# netx90_app register map
File version: 1.0
CPU: CM4 r0p1, little endian, MPU, FPU, 4 interrupt priority bits, 78 interrupts
Registers are 32-bit, read-write, reset 0x0 unless marked. A register's access mark holds for its fields unless they carry their own. Offsets are from the block's base; [hi:lo] are bit positions; {n}, {i} and the like mark numbered series.

## biss0_app
Base 0xFF802100
Same registers: biss1_app 0xFF802200
{0x0+8i} biss_scdata{i}_0 (i=0..6) — Sensor and Actuator Data
  [31:0] SCDATA{i}_0 — Slave{i} (SCD)single cycle data[31:0]
{0x4+8i} biss_scdata{i}_1 (i=0..7) — Sensor and Actuator Data
  [31:0] SCDATA{i}_1 — Slave{i} (SCD)single cycle data[63:32]
0x38 biss_scdata7_0 — Sensor and Actuator Data
  [31:0] SCDATA7_0 — Slave0 (SCD)single cycle data[31:0]
0x80 biss_rdata0 — Register Data
  [31:0] RDATA0 — - Using register access in control communication RDATA0: register data DWord0 - Using command/instructions in control communication IDS: ID-Select, command/instruction addressing combinable
{0x80+4i} biss_rdata{i} (i=1..15) — Register Data
  [31:0] RDATA{i} — register data DWord{i}
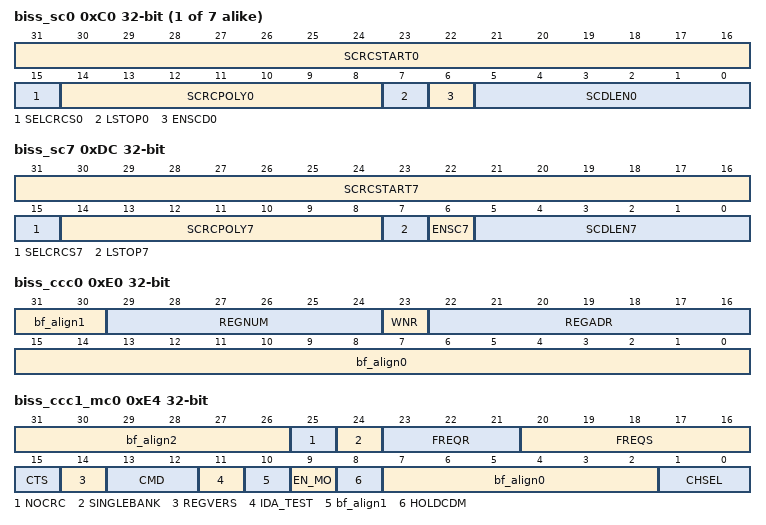
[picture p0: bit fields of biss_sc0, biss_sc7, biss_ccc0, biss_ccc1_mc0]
{0xC0+4i} biss_sc{i} (i=0..6) — Slave Configuration
  [31:16] SCRCSTART{i} — Start value for polynomial SCD CRC calculation
  [15] SELCRCS{i} — Selection between polynomial or length for SCD CRC polynomial 0: CRC bit length in SCRCLENx (see SCRCPOLYx) apply dedicated CRC polynomials 1: CRC polynomial(7:1) in SCRCPOLYx. SELCRCSx = 1 not applicable with CRC polynomial SCRCPOLYx(7:0) = 0x00
  [14:8] SCRCPOLY{i} — - SELCRCx == 0 ( SCRCLENx: polynomial selection by length for SCD CRC check) 0: CRC for single cycle data not present, CRC verification deactivated. SELCRCSx = 0b0 3: CRC polynomial = 0x0b 4: CRC polynomial = 0x13 5: CRC polynomial = 0x25 6: CRC polynomial = 0x43 7: CRC polynomial = 0x89 8: CRC polynomial = 0x12f 16: CRC polynomial = 0x190d9 ..: other CRC length are not permitted with SELCRCSx = 0 - SELCRCx == 1 (SCRCPOLYx: polynomial for SCD CRC check) 0x00 : CRC polynomial 0x00 not applicable with SELCRCSx = 1 0x01.. 0x7f: CRC polynomial for single cycle data = SCRCPOLYx(7:1) + 0x01
  [7] LSTOP{i} — - BISS mode(LSTOPx = Actuator stop bit control) 0: no leading STOP bit on single cycle actuator data 1: leading STOP bit on single cycle actuator data - SSI mode(GRAYSx = Enable SCD gray to binary conversion) 0: SSI single cycle data binary coded 1: SSI single cycle data gray coded
  [6] ENSCD{i} — Enable single cycle data 0: single cycle data not available 1: single cycle data available
  [5:0] SCDLEN{i} — Single cycle data length 0 : single cycle data length = 1 1 : single cycle data length = 2 ... single cycle data length = SCDLENx + 1 62: single cycle data length = 63 63: single cycle data length = 64
0xDC biss_sc7 — Slave Configuration
  [31:16] SCRCSTART7 — Start value for polynomial SCD CRC calculation
  [15] SELCRCS7 — Selection between polynomial or length for SCD CRC polynomial 0: CRC bit length in SCRCLENx (see SCRCPOLYx) apply dedicated CRC polynomials 1: CRC polynomial(7:1) in SCRCPOLYx. SELCRCSx = 1 not applicable with CRC polynomial SCRCPOLYx(7:0) = 0x00
  [14:8] SCRCPOLY7 — - SELCRCx == 0 (SCRCLENx: polynomial selection by length for SCD CRC check) 0: CRC for single cycle data not present, CRC verification deactivated. SELCRCSx = 0b0 3: CRC polynomial = 0x0b 4: CRC polynomial = 0x13 5: CRC polynomial = 0x25 6: CRC polynomial = 0x43 7: CRC polynomial = 0x89 8: CRC polynomial = 0x12f 16: CRC polynomial = 0x190d9 ..: other CRC length are not permitted with SELCRCSx = 0 - SELCRCx == 1 (SCRCPOLYx: polynomial for SCD CRC check) 0x00 : CRC polynomial 0x00 not applicable with SELCRCSx = 1 0x01.. 0x7f: CRC polynomial for single cycle data = SCRCPOLYx(7:1) + 0x01
  [7] LSTOP7 — - BISS mode(LSTOPx = Actuator stop bit control) 0: no leading STOP bit on single cycle actuator data 1: leading STOP bit on single cycle actuator data - SSI mode(GRAYSx = Enable SCD gray to binary conversion) 0: SSI single cycle data binary coded 1: SSI single cycle data gray coded
  [6] ENSC7 — Enable single cycle data 0: single cycle data not available 1: single cycle data available
  [5:0] SCDLEN7 — Single cycle data length 0 : single cycle data length = 1 1 : single cycle data length = 2 ... single cycle data length = SCDLENx + 1 62: single cycle data length = 63 63: single cycle data length = 64
0xE0 biss_ccc0 (reset mask 0x3FFF0000) — Register Communication Configuration
  [31:30] bf_align1 — bitField alignment value for aeabi compatibility
  [29:24] REGNUM — Register data count 0x00 : register count = 1 0x01 ..0x3f: register count = REGNUM(5:0)+1
  [23] WNR — Register access read/write selector 0: read register data 1: write register data
  [22:16] REGADR — Register access start address 0x00 .. 0x7f
  [15:0] bf_align0 — bitField alignment value for aeabi compatibility
0xE4 biss_ccc1_mc0 (reset mask 0x3FFFB03) — Register Communication Configuration / Master Configuration
  [31:26] bf_align2 — bitField alignment value for aeabi compatibility
  [25] NOCRC — CRC for SCD not to be stored in RAM 0: CRC of SCD is stored RAM (only applicable with active CRC verification and CRC polynome > 0) 1: CRC of SCD not to be stored in RAM
  [24] SINGLEBANK — Use of only one RAM bank for SCD 0: two RAM banks are used for SCD 1: one RAM bank is used for SCD
  [23:21] FREQR — Frequency division register communication BiSS B 0 .. 7: freqSens/(2*(FREQ(7:5)+1)) 0: FreqSens/2 1: FreqSens/4 2: FreqSens/8 3: FreqSens/16 4: FreqSens/32 5: FreqSens/64 6: FreqSens/128 7: FreqSens/256
  [20:16] FREQS — Frequency division 0x00: fCLK/2 0x01: fCLK/4 0x02: fCLK/6 0x03: fCLK/8 ... 0x09: fCLK/20 ... 0x0d: fCLK/28 0x0e: fCLK/30 0x0f: fCLK/32 0x10: not permitted 0x11: fCLK/40 0x12: fCLK/60 0x13: fCLK/80 ... 0x1d: fCLK/280 0x1e: fCLK/300 0x1f: fCLK/320
  [15] CTS — Register transmission or instruction selector 0: command/instruction communication 1: register communication
  [14] REGVERS — BiSS model A/B or C selector - Using register access in control communication 0: register communication BiSS A/B 1: register communication BiSS C - Using command/instructions in control communication 0: not applicable with command/instruction communication 1: command communication BiSS C
  [13:12] CMD — - Using register access in control communication SLAVEID[2:1]: slave selector bit2_1 - Using command/instructions in control communication Command of access slave # default 0x00 0x00 .. 0x03: command/instruction 0b00 .. 0b11
  [11] IDA_TEST — - Using register access in control communication SLAVEID[0]: slave selector bit0 - Using command/instructions in control communication IDA_TEST: command/instruction execution control 0: the slaves feedback (IDA) is tested before execution (EX bit after IDA) 1: immediate execution
  [10] bf_align1 — bitField alignment value for aeabi compatibility
  [9] EN_MO — Enable output at MOx for actuator data or delayed start bit 0: MO forced to low 1: Parameterized processing time by master on MO signal active (length: MO_BUSY)
  [8] HOLDCDM — Hold CDM(control data master) 0: clock line high at end of cycle 1: clock line constant with CDM bit until start of next cycle
  [7:2] bf_align0 — bitField alignment value for aeabi compatibility
  [1:0] CHSEL — Channel selector 0: channel 1 used for control communication, channel 2 not used 1: channel 1 used for control communication, channel 2 not used 2: channel 2 used for control communication, channel 1 not used. Note: Channel 2 is not available with IC-MB4 TSSOP24 3: channel 1,2 used for control communication. Note: Channel 2 is not available with IC-MB4 TSSOP24
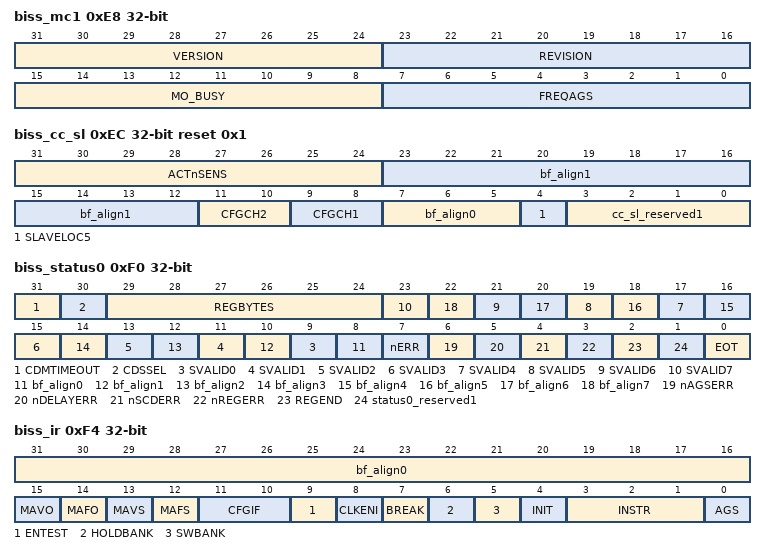
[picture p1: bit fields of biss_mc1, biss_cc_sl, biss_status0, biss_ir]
0xE8 biss_mc1 — Master Configuration
  [31:24] VERSION — Device identifier 0x83: iC-MB3 0x84: iC-MB4 .. 0xff
  [23:16] REVISION — Revision 0x10: Z(first revision) 0x11: Z1 0x12: Y .. 0xff
  [15:8] MO_BUSY — Delay of start bit at output MOx 0x00 .. 0xff: count of MA clocks as the parameterized processing time by master on MO signal Premise: EN_MO = 1
  [7:0] FREQAGS — AutoGetSens Frequency division 0x00.. 0x7b: fCLK/(20*(FREQAGS(6:0)+1)) 0x7c : AGSMIN( the master automatically restarts the next cycle after the prior was finished. AGSMIN is the fastest SCD rate with complete SCD cycles. ) 0x7d.. 0x7f: AGSINFINITE( the master does not automatically restart the next cycle after the prior one was finished. AGSINFINITE requires a trigger event to start the next SCD cycle. ) 0x80.. 0xff: fCLK/(625*(FREQAGS(6:0)+1))
0xEC biss_cc_sl reset 0x1 (reset mask 0xFF000F1F) — Channel Configuration
  [31:24] ACTnSENS — Sensor or actuator data selector 0x00: all slaves are sensors 0x01: slave 0 is actuator 0x02: slave 1 is actuator 0x04: slave 2 is actuator 0x08: slave 3 is actuator 0x10: slave 4 is actuator 0x20: slave 5 is actuator 0x40: slave 6 is actuator 0x80: slave 7 is actuator 0xff: all slaves are actuators
  [23:12] bf_align1 — bitField alignment value for aeabi compatibility
  [11:10] CFGCH2 — Channel 2 configuration 0x00: BiSS B 0x01: BiSS C 0x02: SSI 0x03: channel is not used
  [9:8] CFGCH1 — Channel 1 configuration 0x00: BiSS B 0x01: BiSS C 0x02: SSI 0x03: channel is not used
  [7:5] bf_align0 — bitField alignment value for aeabi compatibility
  [4] SLAVELOC5 — Slave location 0: slaves 4-7 are connected to channel 1 1: slaves 4-7 are connected to channel 2(only available with iC-MB4 QFN28)
  [3:0] cc_sl_reserved1 — no field descpription
0xF0 biss_status0 ro (reset mask 0xFFAAAAFF) — Status Information
  [31] CDMTIMEOUT — CDM(Control Data Master) timeout reached 0: CDMTIMEOUT not reached 1: CDMTIMEOUT reached
  [30] CDSSEL — CDS(Control Data Slave) bit from the selected channel
  [29:24] REGBYTES — Number of valid register data transmission in case of error 0x00 : after transfer: no register communication error 0x01 . 0x3f: after transfer: number of successfully transferred registers before register communication error
  [2n+9] SVALID{n} (n=0..7) — SCDATA{n} validity indication 0: SCD invalid 1: SCD valid The SVALIDx bit indicates the validity of each slaves SCD CRC verification. A prior set SVALIDx bit can be reset by writing 0 into the register.
  [2n+8] bf_align{n} (n=0..7) — bitField alignment value for aeabi compatibility
  [7] nERR — Transmission error (error at NER pin) 0: error 1: no error It is possible to connect other components to pin NER which can also generate an error message; this can then be read out via this bit.
  [6] nAGSERR — AGS error 0: AGS(Automatic Get Sensor data) watchdog error 1: no AGS watchdog error An AGS watchdog error is set during the automatic transmission of sensor data if no new cycle could be initiated; bit AGS in the command register is reset and the automatic request of sensor data aborted.
  [5] nDELAYERR — Missing start bit during register communication 0: delay error 1: no delay error
  [4] nSCDERR — Error in single cycle data transmission 0: error in last single cycle data transmission 1: no error in last single cycle data transmission
  [3] nREGERR — Error in register data transmission 0: error in last register data transmission 1: no error in last register data transmission
  [2] REGEND — Register data transmission completed 0: no valid register data available 1: register data transmission completed
  [1] status0_reserved1 — reserved value
  [0] EOT — Data transmission completed 0: data transmission active 1: data transmission finished
0xF4 biss_ir (reset mask 0xFFFF) — Instruction Register
  [31:16] bf_align0 — bitField alignment value for aeabi compatibility
  [15] MAVO — Not selected MA line control level 0: low definition of unselected(CHSEL) MA clock lines 1: high definition of unselected(CHSEL) MA clock lines
  [14] MAFO — Not selected MA line control selection 0: controlling unselected(CHSEL) MA clock line: using MA signal 1: controlling unselected(CHSEL) MA clock line: using MAVS level
  [13] MAVS — Selected MA line control level 0: low definition of selected(CHSEL) MA clock lines 1: high definition of selected(CHSEL) MA clock lines
  [12] MAFS — Selected MA line control selection 0: controlling selected/CHSEL) MA clock line: using MA signal 1: controlling selected(CHSEL) MA clock line: using MAVS level
  [11:10] CFGIF — Configure physical interface 0x00: TTL 0x01: CMOS 0x02: RS422 0x03: LVDS
  [9] ENTEST — Enable test interface 0: device in normal operation mode 1: device in test mode
  [8] CLKENI — Enable internal clock 0: the master clock is generated by an external clock oscillator 1: the master clock is generated by the basic clock of the internal 20MHz oscillator
  [7] BREAK — Data transmission interrupt 0: no change 1: abort data transmission nSCDERR, nREGERR, nDELAYERR, nAGSERR = 1, REGEND = 0 All current actions can be aborted using the BREAK command so that a defined state can be resumed if one of the sensors proves faulty, for example. BREAK= 1 aborts the active data transmission and all status information will be reset.
  [6] HOLDBANK — RAM bank control 0: no bank switching lock permitted 1: bank switching lock permitted During the readout of more than one sensor data register by the controller it is possible that the RAM banks in the master could be swapped over once a sensor data transmission is completed. So that the controller only reads related values bit HOLDBANK should be set at the start of the readout and reset at the end; this suppresses the RAM swap. With the start of a new sensor data cycle previous values are then overwritten by the new sensor data.
  [5] SWBANK — Switch RAM banks 0: RAM banks are not switched 1: RAM banks are switched
  [4] INIT — Start INIT sequence 0: no changes on the data channel 1: initialize data channel
  [3:1] INSTR — SCD control instruction 0b010 : CDM = 0 0b001 : CDM = 1 0b100, 0b110: register communication condition: CDMTIMEOUT = 1 0b111 : register communication(reduced protocol) condition: CDMTIMEOUT = 1 The transmission of sensor data can be triggered via INSTR. With INSTR=0b010 the ccle finishes with a CDM=0. With INSTR= 0b001 the cycle finishes with a CDM=1. A BiSS C register access to a slave can be operated by INSTR=0b100. A reduced protocol for a shorter BiSS C register access to a slave can be operated by INST=0b111.
  [0] AGS — AutoGetSens(Automatic Get Sensordata) 0: no automatic data transmission 1: - start of data transmission after TIMEOUTSENS condition: FREQAGS = AGSMIN - start of data transmission triggered by pin condition: FREQAGS = AGSINFINITE - start of data transmission after timeout With AGS = 0 the master starts the data transmission after finishing writing the instruction register(rising edge of NWR). A nAGSERR error will be generated if the SL line is low, TIMEOUTSENS has not exceeded. If an AGS bit has been set sensor data is read in cyclically according to the cycle frequency set in FREQAGS.
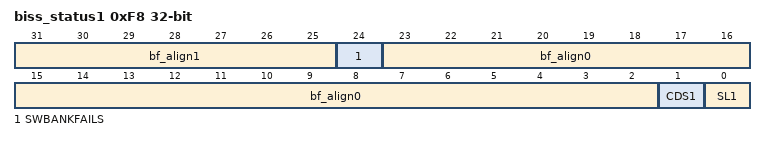
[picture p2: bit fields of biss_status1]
0xF8 biss_status1 ro (reset mask 0x1000003) — Status Information
  [31:25] bf_align1 — bitField alignment value for aeabi compatibility
  [24] SWBANKFAILS — Bank switching status 0: bank switching(SCD) successful 1: bank switching(SCD) not successful
  [23:2] bf_align0 — bitField alignment value for aeabi compatibility
  [1] CDS1 — CDS bit of channel 1 0: CDS = 0 1: CDS = 1
  [0] SL1 — Current SL line level of channel 1 0: SL line level low 1: SL line level high
